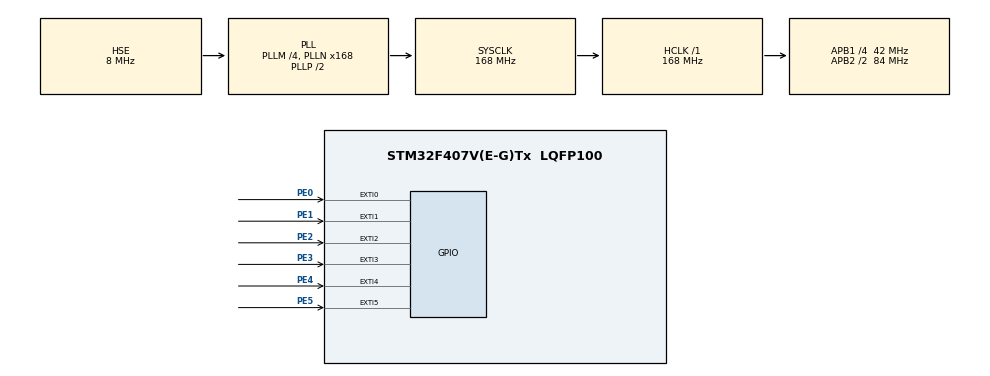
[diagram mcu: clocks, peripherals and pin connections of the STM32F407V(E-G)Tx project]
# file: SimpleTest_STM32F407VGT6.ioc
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Mcu.Family=STM32F4
Mcu.Name=STM32F407V(E-G)Tx
Mcu.Package=LQFP100
NVIC.EXTI0_IRQn=true\:0\:0\:false\:false\:true\:true\:true\:true
NVIC.EXTI1_IRQn=true\:0\:0\:false\:false\:true\:true\:true\:true
NVIC.EXTI2_IRQn=true\:0\:0\:false\:false\:true\:true\:true\:true
NVIC.EXTI3_IRQn=true\:0\:0\:false\:false\:true\:true\:true\:true
NVIC.EXTI4_IRQn=true\:0\:0\:false\:false\:true\:true\:true\:true
NVIC.EXTI9_5_IRQn=true\:0\:0\:false\:false\:true\:true\:true\:true
NVIC.PriorityGroup=NVIC_PRIORITYGROUP_4
PA13.Mode=JTAG_5_pins
PA13.Signal=SYS_JTMS-SWDIO
PA14.Mode=JTAG_5_pins
PA14.Signal=SYS_JTCK-SWCLK
PA15.Mode=JTAG_5_pins
PA15.Signal=SYS_JTDI
PB3.Mode=JTAG_5_pins
PB3.Signal=SYS_JTDO-SWO
PB4.Mode=JTAG_5_pins
PB4.Signal=SYS_JTRST
PE0.Signal=GPXTI0
PE1.Signal=GPXTI1
PE2.Signal=GPXTI2
PE3.Signal=GPXTI3
PE4.Signal=GPXTI4
PE5.Signal=GPXTI5
PH0-OSC_IN.Mode=HSE-External-Oscillator
PH0-OSC_IN.Signal=RCC_OSC_IN
PH1-OSC_OUT.Mode=HSE-External-Oscillator
PH1-OSC_OUT.Signal=RCC_OSC_OUT
ProjectManager.HeapSize=0x200
ProjectManager.StackSize=0x400
ProjectManager.TargetToolchain=MDK-ARM V5.32
RCC.48MHZClocksFreq_Value=84000000
RCC.AHBFreq_Value=168000000
RCC.APB1CLKDivider=RCC_HCLK_DIV4
RCC.APB1Freq_Value=42000000
RCC.APB1TimFreq_Value=84000000
RCC.APB2CLKDivider=RCC_HCLK_DIV2
RCC.APB2Freq_Value=84000000
RCC.APB2TimFreq_Value=168000000
RCC.CortexFreq_Value=168000000
RCC.EnbaleCSS=true
RCC.HCLKFreq_Value=168000000
RCC.HSE_VALUE=8000000
RCC.HSI_VALUE=16000000
RCC.LSE_VALUE=32768
RCC.PLLM=4
RCC.PLLN=168
RCC.PLLSourceVirtual=RCC_PLLSOURCE_HSE
RCC.SYSCLKFreq_VALUE=168000000
RCC.SYSCLKSource=RCC_SYSCLKSOURCE_PLLCLK
RCC.VCOOutputFreq_Value=336000000
board=custom

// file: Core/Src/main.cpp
/* USER CODE BEGIN Header */
/**
  ******************************************************************************
  * @file           : main.c
  * @brief          : Main program body
  ******************************************************************************
  * @attention
  *
  * Copyright (c) 2025 STMicroelectronics.
  * All rights reserved.
  *
  * This software is licensed under terms that can be found in the LICENSE file
  * in the root directory of this software component.
  * If no LICENSE file comes with this software, it is provided AS-IS.
  *
  ******************************************************************************
  */
/* USER CODE END Header */
#include "main.h"

/* USER CODE BEGIN Includes */
#include "LimitSwitch.h"
/* USER CODE END Includes */

/* USER CODE BEGIN PV */
LimitSwitch limitSwitch_1(GPIOE, GPIO_PIN_0, 0, 0, true);

volatile int d = 0;
/* USER CODE END PV */

void SystemClock_Config(void);
static void MX_GPIO_Init(void);
/* USER CODE BEGIN PFP */
void HAL_GPIO_EXTI_Callback(uint16_t GPIO_Pin)
{
  if(GPIO_Pin == GPIO_PIN_0)
  {
    limitSwitch_1.EXTI_Callback();
  }
}
/* USER CODE END PFP */

int main(void)
{

  /* MCU Configuration--------------------------------------------------------*/

  /* Reset of all peripherals, Initializes the Flash interface and the Systick. */
  HAL_Init();

  /* Configure the system clock */
  SystemClock_Config();

  /* Initialize all configured peripherals */
  MX_GPIO_Init();
  /* USER CODE BEGIN 2 */
  limitSwitch_1.init();
  /* USER CODE END 2 */

  /* Infinite loop */
  /* USER CODE BEGIN WHILE */
  while (1)
  {
    d = limitSwitch_1.get();
    HAL_Delay(3);
    /* USER CODE END WHILE */

  }
}

void SystemClock_Config(void)
{
  RCC_OscInitTypeDef RCC_OscInitStruct = {0};
  RCC_ClkInitTypeDef RCC_ClkInitStruct = {0};

  /** Configure the main internal regulator output voltage
  */
  __HAL_RCC_PWR_CLK_ENABLE();
  __HAL_PWR_VOLTAGESCALING_CONFIG(PWR_REGULATOR_VOLTAGE_SCALE1);

  /** Initializes the RCC Oscillators according to the specified parameters
  * in the RCC_OscInitTypeDef structure.
  */
  RCC_OscInitStruct.OscillatorType = RCC_OSCILLATORTYPE_HSE;
  RCC_OscInitStruct.HSEState = RCC_HSE_ON;
  RCC_OscInitStruct.PLL.PLLState = RCC_PLL_ON;
  RCC_OscInitStruct.PLL.PLLSource = RCC_PLLSOURCE_HSE;
  RCC_OscInitStruct.PLL.PLLM = 4;
  RCC_OscInitStruct.PLL.PLLN = 168;
  RCC_OscInitStruct.PLL.PLLP = RCC_PLLP_DIV2;
  RCC_OscInitStruct.PLL.PLLQ = 4;
  if (HAL_RCC_OscConfig(&RCC_OscInitStruct) != HAL_OK)
  {
    Error_Handler();
  }

  /** Initializes the CPU, AHB and APB buses clocks
  */
  RCC_ClkInitStruct.ClockType = RCC_CLOCKTYPE_HCLK|RCC_CLOCKTYPE_SYSCLK
                              |RCC_CLOCKTYPE_PCLK1|RCC_CLOCKTYPE_PCLK2;
  RCC_ClkInitStruct.SYSCLKSource = RCC_SYSCLKSOURCE_PLLCLK;
  RCC_ClkInitStruct.AHBCLKDivider = RCC_SYSCLK_DIV1;
  RCC_ClkInitStruct.APB1CLKDivider = RCC_HCLK_DIV4;
  RCC_ClkInitStruct.APB2CLKDivider = RCC_HCLK_DIV2;

  if (HAL_RCC_ClockConfig(&RCC_ClkInitStruct, FLASH_LATENCY_5) != HAL_OK)
  {
    Error_Handler();
  }

  /** Enables the Clock Security System
  */
  HAL_RCC_EnableCSS();
}

static void MX_GPIO_Init(void)
{
  GPIO_InitTypeDef GPIO_InitStruct = {0};

  /* GPIO Ports Clock Enable */
  __HAL_RCC_GPIOE_CLK_ENABLE();
  __HAL_RCC_GPIOH_CLK_ENABLE();
  __HAL_RCC_GPIOA_CLK_ENABLE();
  __HAL_RCC_GPIOB_CLK_ENABLE();

  /*Configure GPIO pins : PE2 PE3 PE4 PE5
                           PE0 PE1 */
  GPIO_InitStruct.Pin = GPIO_PIN_2|GPIO_PIN_3|GPIO_PIN_4|GPIO_PIN_5
                          |GPIO_PIN_0|GPIO_PIN_1;
  GPIO_InitStruct.Mode = GPIO_MODE_IT_RISING;
  GPIO_InitStruct.Pull = GPIO_NOPULL;
  HAL_GPIO_Init(GPIOE, &GPIO_InitStruct);

  /* EXTI interrupt init*/
  HAL_NVIC_SetPriority(EXTI0_IRQn, 0, 0);
  HAL_NVIC_EnableIRQ(EXTI0_IRQn);

  HAL_NVIC_SetPriority(EXTI1_IRQn, 0, 0);
  HAL_NVIC_EnableIRQ(EXTI1_IRQn);

  HAL_NVIC_SetPriority(EXTI2_IRQn, 0, 0);
  HAL_NVIC_EnableIRQ(EXTI2_IRQn);

  HAL_NVIC_SetPriority(EXTI3_IRQn, 0, 0);
  HAL_NVIC_EnableIRQ(EXTI3_IRQn);

  HAL_NVIC_SetPriority(EXTI4_IRQn, 0, 0);
  HAL_NVIC_EnableIRQ(EXTI4_IRQn);

  HAL_NVIC_SetPriority(EXTI9_5_IRQn, 0, 0);
  HAL_NVIC_EnableIRQ(EXTI9_5_IRQn);

}

void Error_Handler(void)
{
  __disable_irq();
  while (1)
  {
  }
}
